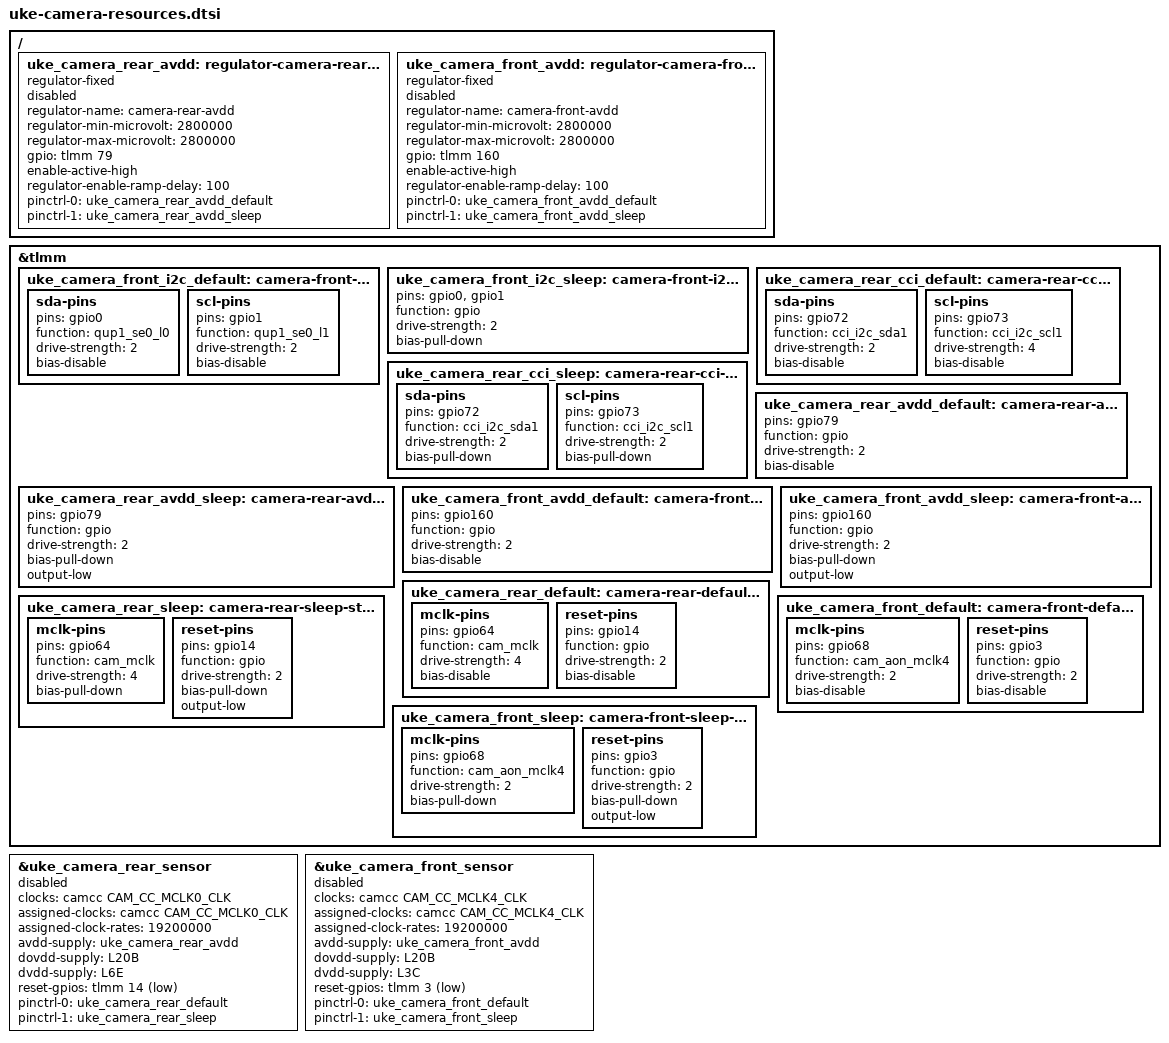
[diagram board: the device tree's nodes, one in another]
// SPDX-License-Identifier: GPL-2.0-only
/*
 * Uke OEM resource translation, not a complete or enabled camera graph.
 * MiCode camera DT 57d2135ee6909ffb7d288a7dc4d82c85d95fc10d:
 * uke-sm8635-camera-sensor.dtsi and cliffs-camera.dtsi.
 * The native board must define both sensor labels from verified topology.
 * Disable the Android camera owners before admitting these consumers.
 */
#include <dt-bindings/gpio/gpio.h>
#include <dt-bindings/clock/qcom,sm7675-camcc.h>

/ {
	uke_camera_rear_avdd: regulator-camera-rear-avdd {
		compatible = "regulator-fixed";
		regulator-name = "camera-rear-avdd";
		regulator-min-microvolt = <2800000>;
		regulator-max-microvolt = <2800000>;
		gpio = <&tlmm 79 GPIO_ACTIVE_HIGH>;
		enable-active-high;
		regulator-enable-ramp-delay = <100>;
		pinctrl-names = "default", "sleep";
		pinctrl-0 = <&uke_camera_rear_avdd_default>;
		pinctrl-1 = <&uke_camera_rear_avdd_sleep>;
		status = "disabled";
	};

	uke_camera_front_avdd: regulator-camera-front-avdd {
		compatible = "regulator-fixed";
		regulator-name = "camera-front-avdd";
		regulator-min-microvolt = <2800000>;
		regulator-max-microvolt = <2800000>;
		gpio = <&tlmm 160 GPIO_ACTIVE_HIGH>;
		enable-active-high;
		regulator-enable-ramp-delay = <100>;
		pinctrl-names = "default", "sleep";
		pinctrl-0 = <&uke_camera_front_avdd_default>;
		pinctrl-1 = <&uke_camera_front_avdd_sleep>;
		status = "disabled";
	};
};

&tlmm {
	uke_camera_front_i2c_default: camera-front-i2c-default-state {
		sda-pins {
			pins = "gpio0";
			function = "qup1_se0_l0";
			drive-strength = <2>;
			bias-disable;
		};
		scl-pins {
			pins = "gpio1";
			function = "qup1_se0_l1";
			drive-strength = <2>;
			bias-disable;
		};
	};

	uke_camera_front_i2c_sleep: camera-front-i2c-sleep-state {
		pins = "gpio0", "gpio1";
		function = "gpio";
		drive-strength = <2>;
		bias-pull-down;
	};

	uke_camera_rear_cci_default: camera-rear-cci-default-state {
		sda-pins {
			pins = "gpio72";
			function = "cci_i2c_sda1";
			drive-strength = <2>;
			bias-disable;
		};
		scl-pins {
			pins = "gpio73";
			function = "cci_i2c_scl1";
			drive-strength = <4>;
			bias-disable;
		};
	};

	uke_camera_rear_cci_sleep: camera-rear-cci-sleep-state {
		sda-pins {
			pins = "gpio72";
			function = "cci_i2c_sda1";
			drive-strength = <2>;
			bias-pull-down;
		};
		scl-pins {
			pins = "gpio73";
			function = "cci_i2c_scl1";
			drive-strength = <2>;
			bias-pull-down;
		};
	};

	uke_camera_rear_avdd_default: camera-rear-avdd-default-state {
		pins = "gpio79";
		function = "gpio";
		drive-strength = <2>;
		bias-disable;
	};

	uke_camera_rear_avdd_sleep: camera-rear-avdd-sleep-state {
		pins = "gpio79";
		function = "gpio";
		drive-strength = <2>;
		bias-pull-down;
		output-low;
	};

	uke_camera_front_avdd_default: camera-front-avdd-default-state {
		pins = "gpio160";
		function = "gpio";
		drive-strength = <2>;
		bias-disable;
	};

	uke_camera_front_avdd_sleep: camera-front-avdd-sleep-state {
		pins = "gpio160";
		function = "gpio";
		drive-strength = <2>;
		bias-pull-down;
		output-low;
	};

	uke_camera_rear_default: camera-rear-default-state {
		mclk-pins {
			pins = "gpio64";
			function = "cam_mclk";
			drive-strength = <4>;
			bias-disable;
		};
		reset-pins {
			pins = "gpio14";
			function = "gpio";
			drive-strength = <2>;
			bias-disable;
		};
	};

	uke_camera_rear_sleep: camera-rear-sleep-state {
		mclk-pins {
			pins = "gpio64";
			function = "cam_mclk";
			drive-strength = <4>;
			bias-pull-down;
		};
		reset-pins {
			pins = "gpio14";
			function = "gpio";
			drive-strength = <2>;
			bias-pull-down;
			output-low;
		};
	};

	uke_camera_front_default: camera-front-default-state {
		mclk-pins {
			pins = "gpio68";
			function = "cam_aon_mclk4";
			drive-strength = <2>;
			bias-disable;
		};
		reset-pins {
			pins = "gpio3";
			function = "gpio";
			drive-strength = <2>;
			bias-disable;
		};
	};

	uke_camera_front_sleep: camera-front-sleep-state {
		mclk-pins {
			pins = "gpio68";
			function = "cam_aon_mclk4";
			drive-strength = <2>;
			bias-pull-down;
		};
		reset-pins {
			pins = "gpio3";
			function = "gpio";
			drive-strength = <2>;
			bias-pull-down;
			output-low;
		};
	};
};

&uke_camera_rear_sensor {
	clocks = <&camcc CAM_CC_MCLK0_CLK>;
	assigned-clocks = <&camcc CAM_CC_MCLK0_CLK>;
	assigned-clock-rates = <19200000>;
	avdd-supply = <&uke_camera_rear_avdd>;
	dovdd-supply = <&L20B>;
	dvdd-supply = <&L6E>;
	reset-gpios = <&tlmm 14 GPIO_ACTIVE_LOW>;
	pinctrl-names = "default", "sleep";
	pinctrl-0 = <&uke_camera_rear_default>;
	pinctrl-1 = <&uke_camera_rear_sleep>;
	status = "disabled";
};

&uke_camera_front_sensor {
	clocks = <&camcc CAM_CC_MCLK4_CLK>;
	assigned-clocks = <&camcc CAM_CC_MCLK4_CLK>;
	assigned-clock-rates = <19200000>;
	avdd-supply = <&uke_camera_front_avdd>;
	dovdd-supply = <&L20B>;
	dvdd-supply = <&L3C>;
	reset-gpios = <&tlmm 3 GPIO_ACTIVE_LOW>;
	pinctrl-names = "default", "sleep";
	pinctrl-0 = <&uke_camera_front_default>;
	pinctrl-1 = <&uke_camera_front_sleep>;
	status = "disabled";
};
